# SAMA7D65D2GN8 register map
Vendor: Microchip Technology; Series: SAMA7D6; File version: 0
Registers are 32-bit, read-write, reset 0x0 unless marked. A register's access mark holds for its fields unless they carry their own. Offsets are from the block's base; [hi:lo] are bit positions; {n}, {i} and the like mark numbered series.

## AES — Advanced Encryption Standard
Base 0xE1600000
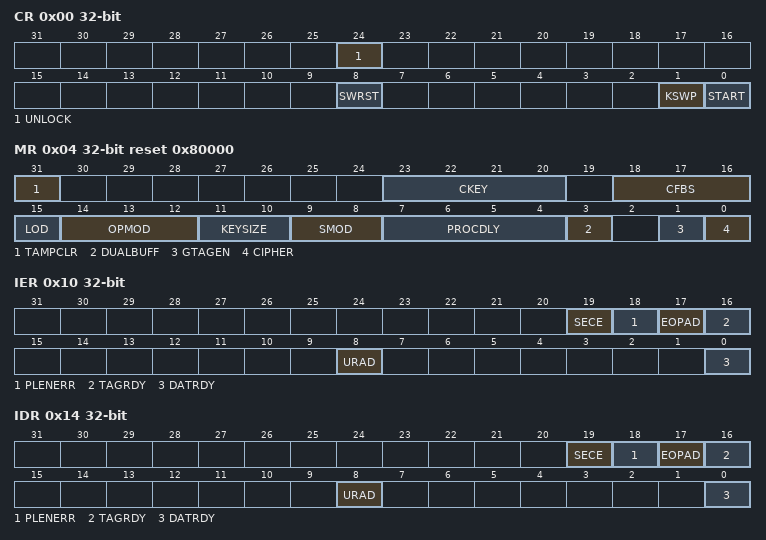
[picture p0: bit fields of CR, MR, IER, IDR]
0x00 CR wo — Control Register
  [24] UNLOCK — Unlock Processing
    0=No effect; 1=Unlocks the processing in case an abnormal event is detected if AES_WPMR.ACTION > 0
  [8] SWRST — Software Reset
    0=No effect; 1=Resets the AES. A software-triggered reset of the AES interface is performed.
  [1] KSWP — Key Swap
    0=No effect; 1=Activates the set of key registers defined by AES_EMR if AES_EMR.PKRS has been changed
  [0] START — Start Processing
    0=No effect; 1=Starts a manual encryption/decryption process
0x04 MR reset 0x80000 — Mode Register
  [31] TAMPCLR — Tamper Clear Enable
    0=A tamper detection event has no effect on the AES_KEYWRx key; 1=A tamper detection event immediately clears the AES_KEYWRx key
  [23:20] CKEY — Key
    14=PASSWD (This field must be written with 0xE the first time AES_MR is programmed. For subsequent programming of AES_MR, any value can be written, including that of 0xE. Always reads as 0.)
  [18:16] CFBS — Cipher Feedback Data Size
    0=SIZE_128BIT (128-bit); 1=SIZE_64BIT (64-bit); 2=SIZE_32BIT (32-bit); 3=SIZE_16BIT (16-bit); 4=SIZE_8BIT (8-bit)
  [15] LOD — Last Output Data Mode
    0=No effect; 1=The DATRDY flag is cleared when at least one of the Input Data registers is written. No more Output Data register reads are necessary between consecutive encryptions/decryptions (see Section 5.8 'Last Output Data Mode (CBC-MAC)').
  [14:12] OPMOD — Operating Mode
    0=ECB (ECB: Electronic Codebook mode); 1=CBC (CBC: Cipher Block Chaining mode); 2=OFB (OFB: Output Feedback mode); 3=CFB (CFB: Cipher Feedback mode); 4=CTR (CTR: Counter mode (16-bit internal counter)); 5=GCM (GCM: Galois/Counter mode); 6=XTS (XTS: XEX-based tweaked-codebook mode)
  [11:10] KEYSIZE
    0=AES128 (AES Key Size is 128 bits); 1=AES192 (AES Key Size is 192 bits); 2=AES256 (AES Key Size is 256 bits)
  [9:8] SMOD — Start Mode
    0=MANUAL_START (Manual Mode); 1=AUTO_START (Auto Mode); 2=IDATAR0_START (AES_IDATAR0 access only Auto Mode (DMA))
  [7:4] PROCDLY — Processing Delay
  [3] DUALBUFF — Dual Input Buffer
    0=INACTIVE (AES_IDATARx cannot be written during processing of previous block.); 1=ACTIVE (AES_IDATARx can be written during processing of previous block when SMOD = 2. It speeds up the overall runtime of large files.)
  [1] GTAGEN — GCM Automatic Tag Generation Enable
    0=Automatic GCM Tag generation disabled; 1=Automatic GCM Tag generation enabled
  [0] CIPHER — Processing Mode
    0=Decrypts data; 1=Encrypts data
0x10 IER wo — Interrupt Enable Register
  [19] SECE — Security and/or Safety Event Interrupt Enable
  [18] PLENERR — Padding Length Error Interrupt Enable
  [17] EOPAD — End of Padding Interrupt Enable
  [16] TAGRDY — GCM Tag Ready Interrupt Enable
  [8] URAD — Unspecified Register Access Detection Interrupt Enable
  [0] DATRDY — Data Ready Interrupt Enable
0x14 IDR wo — Interrupt Disable Register
  [19] SECE — Security and/or Safety Event Interrupt Disable
  [18] PLENERR — Padding Length Error Interrupt Disable
  [17] EOPAD — End of Padding Interrupt Disable
  [16] TAGRDY — GCM Tag Ready Interrupt Disable
  [8] URAD — Unspecified Register Access Detection Interrupt Disable
  [0] DATRDY — Data Ready Interrupt Disable
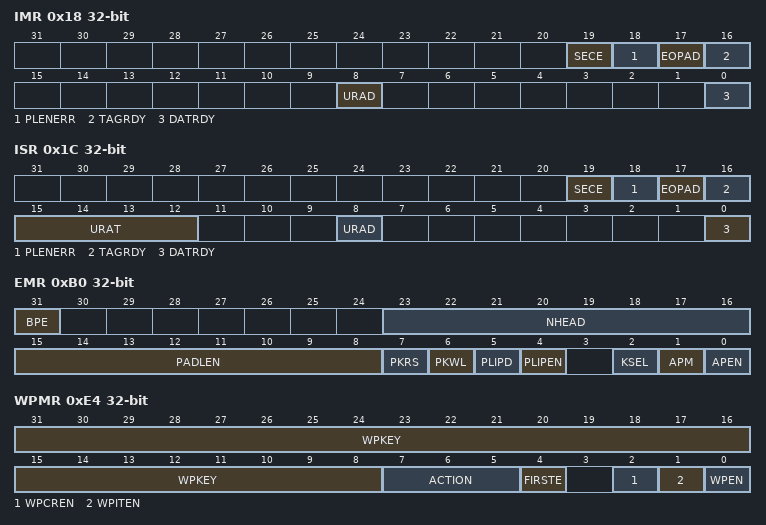
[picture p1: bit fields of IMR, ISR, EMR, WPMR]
0x18 IMR ro — Interrupt Mask Register
  [19] SECE — Security and/or Safety Event Interrupt Mask
  [18] PLENERR — Padding Length Error Interrupt Mask
  [17] EOPAD — End of Padding Interrupt Mask
  [16] TAGRDY — GCM Tag Ready Interrupt Mask
  [8] URAD — Unspecified Register Access Detection Interrupt Mask
  [0] DATRDY — Data Ready Interrupt Mask
0x1C ISR ro — Interrupt Status Register
  [19] SECE — Security and/or Safety Event (cleared on read)
    0=There is no security report in AES_WPSR; 1=One security flag is set in AES_WPSR
  [18] PLENERR — Padding Length Error
    0=No Padding Length Error occurred; 1=Padding Length Error detected
  [17] EOPAD — End of Padding
    0=Padding is not over; 1=The padding phase is over
  [16] TAGRDY — GCM Tag Ready
    0=GCM Tag is not valid; 1=GCM Tag generation is complete (cleared by reading GCM Tag, starting another processing or when writing a new key)
  [15:12] URAT — Unspecified Register Access (cleared by writing SWRST in AES_CR)
    0=IDR_WR_PROCESSING (Input Data register written during the data processing when SMOD = 2 mode.); 1=ODR_RD_PROCESSING (Output Data register read during the data processing.); 2=MR_WR_PROCESSING (Mode register written during the data processing.); 3=ODR_RD_SUBKGEN (Output Data register read during the sub-keys generation.); 4=MR_WR_SUBKGEN (Mode register written during the sub-keys generation.); 5=WOR_RD_ACCESS (Write-only register read access.)
  [8] URAD — Unspecified Register Access Detection Status (cleared by writing SWRST in AES_CR)
    0=No unspecified register access has been detected since the last SWRST; 1=At least one unspecified register access has been detected since the last SWRST
  [0] DATRDY — Data Ready (cleared by setting bit START or bit SWRST in AES_CR or by reading AES_ODATARx)
    0=Output data not valid; 1=Encryption or decryption process is completed
{0x20+4i} KEYWR[{i}] (i=0..7) wo — Key Word Register x
  [31:0] KEYW — Key Word
{0x40+4i} IDATAR[{i}] (i=0..3) wo — Input Data Register x
  [31:0] IDATA — Input Data Word
{0x50+4i} ODATAR[{i}] (i=0..3) ro — Output Data Register x
  [31:0] ODATA — Output Data
{0x60+4i} IVR[{i}] (i=0..3) wo — Initialization Vector Register x
  [31:0] IV — Initialization Vector
0x70 AADLENR — Additional Authenticated Data Length Register
  [31:0] AADLEN — Additional Authenticated Data Length
0x74 CLENR — Plaintext/Ciphertext Length Register
  [31:0] CLEN — Plaintext/Ciphertext Length
{0x78+4i} GHASHR[{i}] (i=0..3) — GCM Intermediate Hash Word Register x
  [31:0] GHASH — Intermediate GCM Hash Word
{0x88+4i} TAGR[{i}] (i=0..3) ro — GCM Authentication Tag Word Register x
  [31:0] TAG — GCM Authentication Tag
0x98 CTRR ro — GCM Encryption Counter Value Register
  [31:0] CTR — GCM Encryption Counter
{0x9C+4i} GCMHR[{i}] (i=0..3) — GCM H Word Register x
  [31:0] H — GCM H Word
0xB0 EMR — Extended Mode Register
  [31] BPE — Block Processing End
    0=The AES_ISR.DATRDY flag reports only the end message encryption processing. No intermediate block processing is reported when SMOD=2. When a DMA is used to transfer data, BPE must be cleared.; 1=The AES_ISR.DATRDY flag reports each end of block processing when SMOD=2. When AES_IDATARx are not loaded by a DMA and SMOD=2, this bit can be written to 1 to rise the AES_ISR.DATRDY flag when a new data block can be written.
  [23:16] NHEAD — IPSec Next Header
  [15:8] PADLEN — Auto-Padding Length
  [7] PKRS — Private Key Internal Register Select
    0=The key used by the AES is in the AES_KEYWRx registers; 1=The key used by the AES is in the Private Key internal registers written via the Private Key bus
  [6] PKWL — Private Key Write Lock
    0=The Private Key internal registers can be written multiple times via the Private Key bus; 1=The Private Key internal registers can be written only once via the Private Key bus until hardware reset
  [5] PLIPD — Protocol Layer Improved Performance Decipher
    0=Protocol layer improved performance is in Ciphering mode; 1=Protocol layer improved performance is in Deciphering mode
  [4] PLIPEN — Protocol Layer Improved Performance Enable
    0=Protocol layer improved performance is disabled; 1=Protocol layer improved performance is enabled
  [2] KSEL — Key Selection for Encryption/Decryption
    0=Selects the first key loaded by software; 1=Selects the second key loaded by software
  [1] APM — Auto-Padding Mode
    0=Auto-Padding is performed according to the IPSec standard; 1=Auto-Padding is performed according to the SSL standard
  [0] APEN — Auto-Padding Enable
    0=Auto-Padding feature is disabled; 1=Auto-Padding feature is enabled
0xB4 BCNT — Byte Counter Register
  [31:0] BCNT — Auto-Padding Byte Counter
{0xC0+4i} TWR[{i}] (i=0..3) — Tweak Word Register x
  [31:0] TWEAK — Tweak Word
{0xD0+4i} ALPHAR[{i}] (i=0..3) wo — Alpha Word Register x
  [31:0] ALPHA — Alpha Word
0xE4 WPMR — Write Protection Mode Register
  [31:8] WPKEY — Write Protection Key
    0x414553=PASSWD (Writing any other value in this field aborts the write operation of the WPEN,WPITEN,WPCREN bits. Always reads as 0.)
  [7:5] ACTION — Action on Abnormal Event Detection
    0=REPORT_ONLY (No action (stop or clear key) is performed when one of PKRPVS, WPVS, CGD, SEQE, or SWE flags is set.); 1=LOCK_PKRPVS_WPVS_SWE (If a processing is in progress when the AES_WPSR.PKRPVS/WPVS/SWE event detection occurs, the current processing is ended normally but no other processing is started while a AES_CR.UNLOCK command is issued.); 2=LOCK_CGD_SEQE (If a processing is in progress when the AES_WPSR.CGD/SEQE event detection occurs, the current processing is ended normally but no other processing is started while a AES_CR.UNLOCK command is issued.); 3=LOCK_ANY_EV (If a processing is in progress when the AES_WPSR.PKRPVS/WPVS/CGD/SEQE/SWE events detection occurs, the current processing is ended normally but no other processing is started while a AES_CR.UNLOCK command is issued.); 4=CLEAR_PKRPVS_WPVS_SWE (If a processing is in progress when the AES_WPSR.PKRPVS/WPVS/SWE events detection occurs, the current processing is ended normally but no other processing is started while a AES_CR.UNLOCK command is issued. Moreover, the AES_KEYWRx key is immediately cleared.); 5=CLEAR_CGD_SEQE (If a processing is in progress when the AES_WPSR.CGD/SEQE events detection occurs, the current processing is ended normally but no other processing is started while a AES_CR.UNLOCK command is issued. Moreover, the AES_KEYWRx key is immediately cleared.); 6=CLEAR_ANY_EV (If a processing is in progress when the AES_WPSR.PKRPVS/WPVS/CGD/SEQE/SWE events detection occurs, the current processing is ended normally but no other processing is started while a AES_CR.UNLOCK command is issued. Moreover, the AES_KEYWRx key is immediately cleared.)
  [4] FIRSTE — First Error Report Enable
    0=The last write protection violation source is reported in AES_WPSR.WPVSRC and the last software control error type is reported in AES_WPSR.SWETYP. The AES_ISR.SECE flag is set at the first error occurrence within a series.; 1=Only the first write protection violation source is reported in AES_WPSR.WPVSRC and only the first software control error type is reported in AES_WPSR.SWETYP. The AES_ISR.SECE flag is set at the first error occurrence within a series.
  [2] WPCREN — Write Protection Control Enable
    0=Disables the write protection on control register if WPKEY corresponds to 0x414553 ('AES' in ASCII); 1=Enables the write protection on control register if WPKEY corresponds to 0x414553 ('AES' in ASCII)
  [1] WPITEN — Write Protection Interruption Enable
    0=Disables the write protection on interrupt registers if WPKEY corresponds to 0x414553 ('AES' in ASCII); 1=Enables the write protection on interrupt registers if WPKEY corresponds to 0x414553 ('AES' in ASCII)
  [0] WPEN — Write Protection Configuration Enable
    0=Disables the write protection on configuration registers if WPKEY corresponds to 0x414553 ('AES' in ASCII); 1=Enables the write protection on configuration registers if WPKEY corresponds to 0x414553 ('AES' in ASCII)
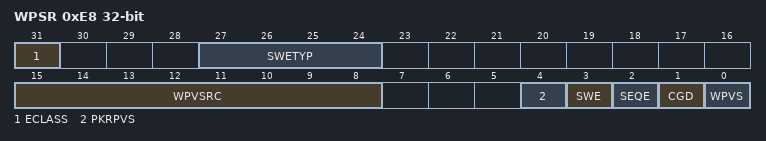
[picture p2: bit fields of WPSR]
0xE8 WPSR ro — Write Protection Status Register
  [31] ECLASS — Software Error Class (cleared on read)
    0=WARNING (An abnormal access that does not affect system functionality); 1=ERROR (An access is performed into key, input data, control registers while the AES is performing an encryption/decryption or a start is request by software or DMA while the key is not fully configured.)
  [27:24] SWETYP — Software Error Type (cleared on read)
    0=READ_WO (A write-only register has been read (Warning).); 1=WRITE_RO (AES is enabled and a write access has been performed on a read-only register (Warning).); 2=UNDEF_RW (Access to an undefined address (Warning).); 3=CTRL_START (Abnormal use of AES_CR.START command when DMA access is configured.); 4=WEIRD_ACTION (A key write, init value write, output data read, AES_MR and AES_EMR write, GCM configuration registers write, AES_TWRx and AES_ALPHARx registers write, AES_BCNT write, Private Key bus access has been performed while a current processing is in progress (abnormal).); 5=INCOMPLETE_KEY (A tentative of start is required while the key is not fully loaded into the AES_KEYWRx registers.)
  [15:8] WPVSRC — Write Protection Violation Source
  [4] PKRPVS — Private Key Internal Register Protection Violation Status (cleared on read)
    0=No Private Key internal register access violation has occurred since the last read of AES_WPSR; 1=A Private Key internal register access violation has occurred since the last read of AES_WPSR
  [3] SWE — Software Control Error (cleared on read)
    0=No software error has occurred since the last read of AES_WPSR; 1=A software error has occurred since the last read of AES_WPSR. The field SWETYP details the type of software error; the associated incorrect software access is reported in the field WPVSRC (if WPVS=0).
  [2] SEQE — Internal Sequencer Error (cleared on read)
    0=No peripheral internal sequencer error has occurred since the last read of AES_WPSR; 1=A peripheral internal sequencer error has occurred since the last read of AES_WPSR. This flag can only be set under abnormal operating conditions.
  [1] CGD — Clock Glitch Detected (cleared on read)
    0=The clock monitoring circuitry has not been corrupted since the last read of AES_WPSR. Under normal operating conditions, this bit is always cleared.; 1=The clock monitoring circuitry has been corrupted since the last read of AES_WPSR. This flag can only be set in case of an abnormal clock signal waveform (glitch).
  [0] WPVS — Write Protection Violation Status (cleared on read)
    0=No write protect violation has occurred since the last read of AES_WPSR; 1=A write protect violation has occurred since the last read of AES_WPSR. The address offset of the violated register is reported into field WPVSRC.

## Notices in the file
Copyright (c) 2026 Microchip Technology Inc.
SPDX-License-Identifier: Apache-2.0
Licensed under the Apache License, Version 2.0 (the "License");
you may not use this file except in compliance with the License.
You may obtain a copy of the License at
http://www.apache.org/licenses/LICENSE-2.0
Unless required by applicable law or agreed to in writing, software
distributed under the License is distributed on an "AS IS" BASIS,
WITHOUT WARRANTIES OR CONDITIONS OF ANY KIND, either express or implied.
See the License for the specific language governing permissions and
limitations under the License.
